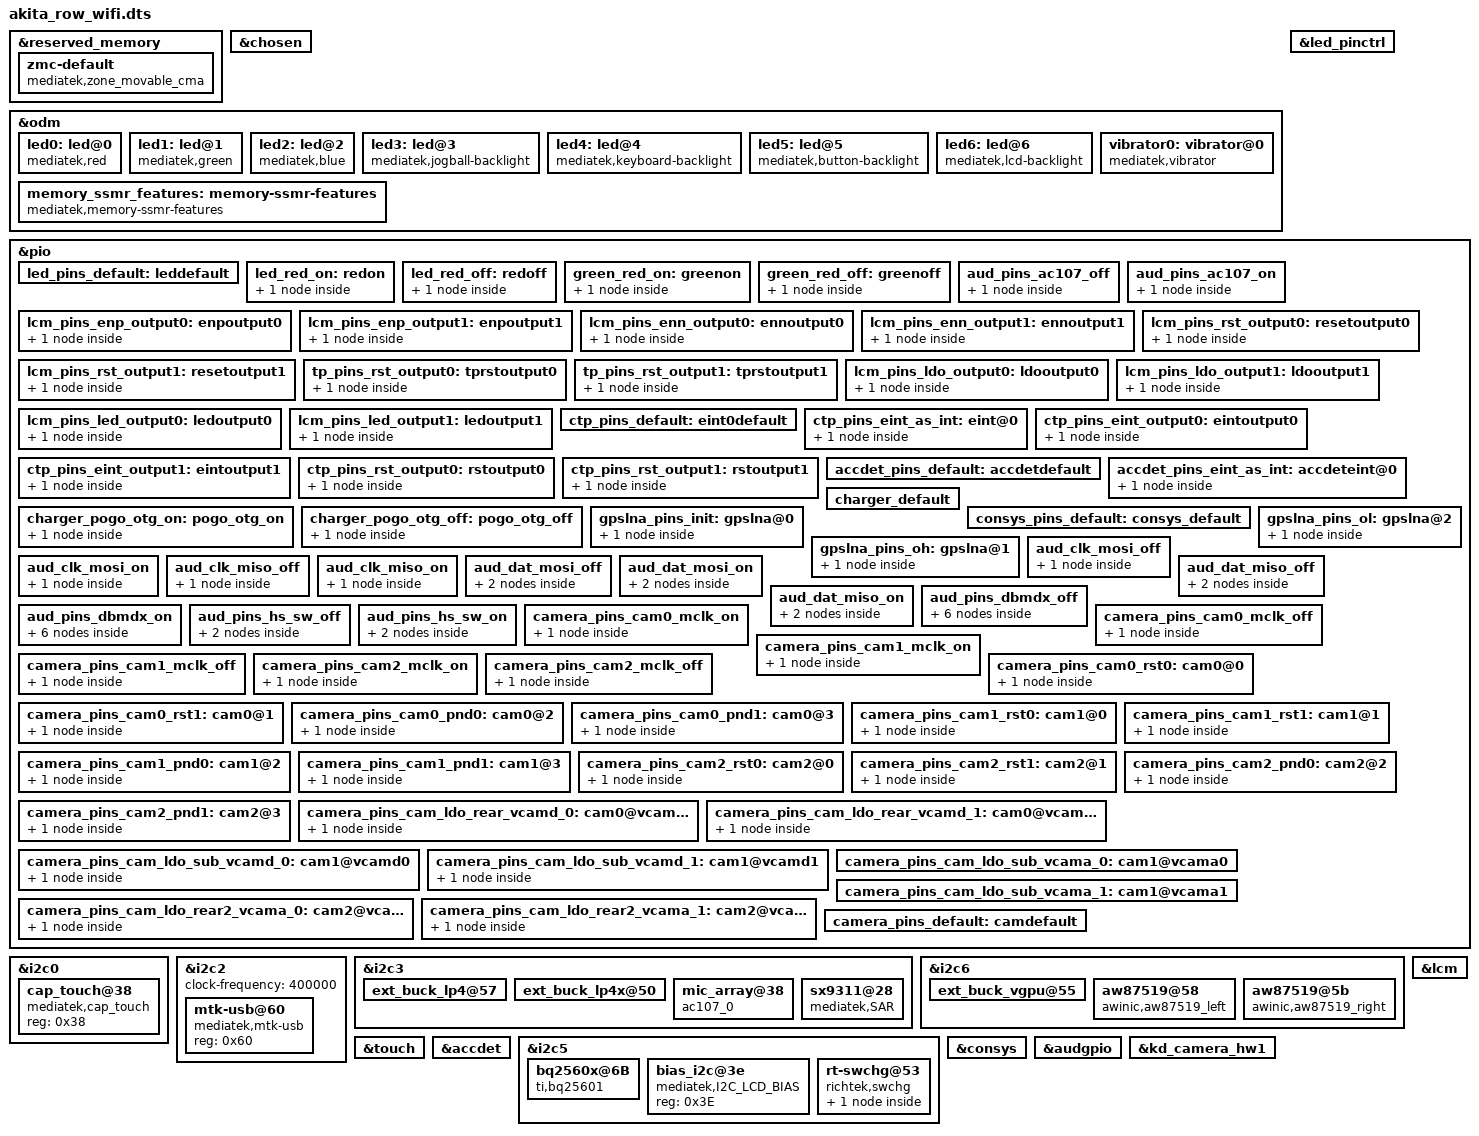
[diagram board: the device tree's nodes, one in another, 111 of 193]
#include <dt-bindings/interrupt-controller/arm-gic.h>
#include <dt-bindings/interrupt-controller/irq.h>
#include <dt-bindings/pinctrl/mt6761-pinfunc.h>
#include <dt-bindings/mmc/mt6761-msdc.h>
#include <dt-bindings/clock/mt6761-clk.h>

/dts-v1/;
/plugin/;

&reserved_memory {
	#address-cells = <2>;
	#size-cells = <2>;
	ranges;

	zmc-default {
		compatible = "mediatek,zone_movable_cma";
		size = <0 0xffc00000>;
		alignment = <0 0x10000000>;
		alloc-ranges = <0 0xc0000000 1 0x00000000>;
	};
};

/* chosen */
&chosen {

	/* fpga may has no lk, we need to specify display info here */
	/* fb buffer is reserved using this dts by memory node above */
	atag,videolfb-fb_base_h = <0x0>;
	atag,videolfb-fb_base_l = <0x5e605000>;
	atag,videolfb-islcmfound = <1>;
	/* because no lk, so lcm is not inited */
	atag,videolfb-islcm_inited = <0>;
	atag,videolfb-fps= <6000>;
	atag,videolfb-vramSize= <0x017bb000>;
	atag,videolfb-lcmname= "nt35521_hd_dsi_vdo_truly_rt5081_drv";
};

&odm {
	led0:led@0 {
		compatible = "mediatek,red";
		led_mode = <2>;
		data = <1>;
		pwm_config = <0 0 0 0 0>;
	};
	led1:led@1 {
		compatible = "mediatek,green";
		led_mode = <2>;
		data = <1>;
		pwm_config = <0 0 0 0 0>;
	};
	led2:led@2 {
		compatible = "mediatek,blue";
		led_mode = <3>;
		data = <2>;
		pwm_config = <0 0 0 0 0>;
	};
	led3:led@3 {
		compatible = "mediatek,jogball-backlight";
		led_mode = <0>;
		data = <1>;
		pwm_config = <0 0 0 0 0>;
	};
	led4:led@4 {
		compatible = "mediatek,keyboard-backlight";
		led_mode = <0>;
		data = <1>;
		pwm_config = <0 0 0 0 0>;
	};
	led5:led@5 {
		compatible = "mediatek,button-backlight";
		led_mode = <0>;
		data = <1>;
		pwm_config = <0 0 0 0 0>;
	};
	led6:led@6 {
		compatible = "mediatek,lcd-backlight";
		led_mode = <5>;
		data = <1>;
		pwm_config = <0 0 0 0 0>;
	};
	vibrator0:vibrator@0 {
		compatible = "mediatek,vibrator";
		vib_timer = <25>;
		vib_limit = <9>;
		vib_vol= <9>;
	};
	memory_ssmr_features: memory-ssmr-features {
		compatible = "mediatek,memory-ssmr-features";
		svp-size = <0 0>;
		iris-recognition-size = <0 0>;
		2d_fr-size = <0 0>;
		tui-size = <0 0>;
		wfd-size = <0 0>;
		prot-sharedmem-size = <0 0>;
	};
};

&led_pinctrl {
	pinctrl-names = "default", "red_on", "red_off", "green_on", "green_off";
	pinctrl-0 = <&led_pins_default>;
	pinctrl-1 = <&led_red_on>;
	pinctrl-2 = <&led_red_off>;
	pinctrl-3 = <&green_red_on>;
	pinctrl-4 = <&green_red_off>;
	status = "okay";
};

&pio {
	led_pins_default: leddefault {
	};
	led_red_on: redon {
		pins_cmd_dat {
			pinmux = <PINMUX_GPIO4__FUNC_GPIO4>;
			slew-rate = <1>;
			output-high;
		};
	};
	led_red_off: redoff {
		pins_cmd_dat {
			pinmux = <PINMUX_GPIO4__FUNC_GPIO4>;
			slew-rate = <1>;
			output-low;
		};
	};
	green_red_on:greenon {
		pins_cmd_dat {
			pinmux = <PINMUX_GPIO0__FUNC_GPIO0>;
			slew-rate = <1>;
			output-high;
		};
	};
	green_red_off: greenoff {
		pins_cmd_dat {
			pinmux = <PINMUX_GPIO0__FUNC_GPIO0>;
			slew-rate = <1>;
			output-low;
		};
	};
};


&i2c0 {
    cap_touch@38 {
        compatible = "mediatek,cap_touch" ;
        reg = < 0x38 > ;
        status = "okay" ;
    };
};

&i2c2 {
	#address-cells = <1>;
	#size-cells = <0>;
	clock-frequency = <400000>;

	mtk-usb@60 {
		compatible = "mediatek,mtk-usb";
		reg = <0x60>;
		status = "okay";
	};
};

&i2c3 {
	ext_buck_lp4@57 {
		regulator-name ="ext_buck_vdd2";
		regulator-min-microvolt = <300000>;
		regulator-max-microvolt = <1300000>;
		vsel_pin = <0>;
	};

	ext_buck_lp4x@50 {
		regulator-name ="ext_buck_vddq";
		regulator-min-microvolt = <300000>;
		regulator-max-microvolt = <1300000>;
		vsel_pin = <1>;
	};

	mic_array@38{
		compatible = "ac107_0";
		reg = <0x38>;
		pinctrl-names = "state_power_off","state_power_on";
		pinctrl-0 = <&aud_pins_ac107_off>;
		pinctrl-1 = <&aud_pins_ac107_on>;
	};

    sx9311@28 {
        compatible = "mediatek,SAR";
        reg = <0x28>;
	    interrupt-parent = <&pio>;
	    interrupts = <11 IRQ_TYPE_EDGE_FALLING 11 0>;
     	int-gpio = <&pio 11 0>;
        polling_mode			= <0>;
	    power_id   				= <0xffff>;
	    Semtech,reg-init        = < 0x03 0x70
		    						0x04 0x00
                                    0x10 0x27
		    						0x11 0x00
		    						0x12 0x0b
		    						0x13 0x0A
		    						0x14 0x25
			    					0x15 0xC3
			    					0x16 0x20 
			    					0x17 0x4C
			    					0x18 0x28 
			    					0x19 0x38
			    					0x1A 0x10
			    					0x1B 0x00
			    					0x1C 0x00
			    					0x1D 0x00
			    					0x1E 0x00
			    					0x1F 0x00
			    					0x20 0x00
			    					0x21 0x18
			    					0x22 0x25
			    					0x23 0x00
			    					0x2A 0x01>;
        status = "okay";
    };
};

&pio {
	aud_pins_ac107_off: aud_pins_ac107_off {
		pins_cmd_dat {
			pinmux = <PINMUX_GPIO87__FUNC_GPIO87>;
			slew-rate = <1>;
			output-low;
		};
	};
	aud_pins_ac107_on: aud_pins_ac107_on{
		pins_cmd_dat {
			pinmux = <PINMUX_GPIO87__FUNC_GPIO87>;
			slew-rate = <1>;
			output-high;
		};
	};
};

&i2c6 {
	ext_buck_vgpu@55 {
		regulator-name ="ext_buck_vgpu";
		regulator-min-microvolt = <300000>;
		regulator-max-microvolt = <1300000>;
		vsel_pin = <2>;
	};

	aw87519@58 {
		compatible = "awinic,aw87519_left";
		reg = <0x58>;
		reset-gpio = <&pio 174 0>;
		status = "okay";
	};

	aw87519@5b {
		compatible = "awinic,aw87519_right";
		reg = <0x5b>;
		reset-gpio = <&pio 153 0>;
		status = "okay";
	};
};

/*LCM start*/
&lcm {
	pinctrl-names = "state_enp_output0", "state_enp_output1",
			"state_enn_output0", "state_enn_output1",
			"state_reset_output0", "state_reset_output1",
			"state_tp_reset_output0", "state_tp_reset_output1",
			"state_ldo_output0", "state_ldo_output1",
			"state_led_output0", "state_led_output1";
	pinctrl-0 = <&lcm_pins_enp_output0>;
	pinctrl-1 = <&lcm_pins_enp_output1>;
	pinctrl-2 = <&lcm_pins_enn_output0>;
	pinctrl-3 = <&lcm_pins_enn_output1>;
	pinctrl-4 = <&lcm_pins_rst_output0>;
	pinctrl-5 = <&lcm_pins_rst_output1>;
	pinctrl-6 = <&tp_pins_rst_output0>;
	pinctrl-7 = <&tp_pins_rst_output1>;
	pinctrl-8 = <&lcm_pins_ldo_output0>;
	pinctrl-9 = <&lcm_pins_ldo_output1>;
	pinctrl-10 = <&lcm_pins_led_output0>;
	pinctrl-11 = <&lcm_pins_led_output1>;
	status = "okay";
};
&pio {
	lcm_pins_enp_output0: enpoutput0 {
		pins_cmd_dat {
			pinmux = <PINMUX_GPIO167__FUNC_GPIO167>;
			slew-rate = <1>;
			output-low;
		};
	};
	lcm_pins_enp_output1: enpoutput1 {
		pins_cmd_dat {
			pinmux = <PINMUX_GPIO167__FUNC_GPIO167>;
			slew-rate = <1>;
			output-high;
		};
	};
	lcm_pins_enn_output0: ennoutput0 {
		pins_cmd_dat {
			pinmux = <PINMUX_GPIO168__FUNC_GPIO168>;
			slew-rate = <1>;
			output-low;
		};
	};
	lcm_pins_enn_output1: ennoutput1 {
		pins_cmd_dat {
			pinmux = <PINMUX_GPIO168__FUNC_GPIO168>;
			slew-rate = <1>;
			output-high;
		};
	};
	lcm_pins_rst_output0: resetoutput0 {
		pins_cmd_dat {
			pinmux = <PINMUX_GPIO45__FUNC_GPIO45>;
			slew-rate = <1>;
			output-low;
		};
	};
	lcm_pins_rst_output1: resetoutput1 {
		pins_cmd_dat {
			pinmux = <PINMUX_GPIO45__FUNC_GPIO45>;
			slew-rate = <1>;
			output-high;
		};
	};
	tp_pins_rst_output0: tprstoutput0 {
		pins_cmd_dat {
			pinmux = <PINMUX_GPIO172__FUNC_GPIO172>;
			slew-rate = <1>;
			output-low;
		};
	};
	tp_pins_rst_output1: tprstoutput1 {
		pins_cmd_dat {
			pinmux = <PINMUX_GPIO172__FUNC_GPIO172>;
			slew-rate = <1>;
			output-high;
		};
	};
	lcm_pins_ldo_output0: ldooutput0 {
		pins_cmd_dat {
			pinmux = <PINMUX_GPIO152__FUNC_GPIO152>;
			slew-rate = <1>;
			output-low;
		};
	};
	lcm_pins_ldo_output1: ldooutput1 {
		pins_cmd_dat {
			pinmux = <PINMUX_GPIO152__FUNC_GPIO152>;
			slew-rate = <1>;
			output-high;
		};
	};
	lcm_pins_led_output0: ledoutput0 {
		pins_cmd_dat {
			pinmux = <PINMUX_GPIO154__FUNC_GPIO154>;
			slew-rate = <1>;
			output-low;
		};
	};
	lcm_pins_led_output1: ledoutput1 {
		pins_cmd_dat {
			pinmux = <PINMUX_GPIO154__FUNC_GPIO154>;
			slew-rate = <1>;
			output-high;
		};
	};
};
/*LCM end*/

#include "d8-spi-melon.dtsi"

/* TOUCH start */
&touch {
	tpd-resolution = <800 1280>;
	use-tpd-button = <0>;
	tpd-key-num = <3>;
	tpd-key-local= <139 172 158 0>;
	tpd-key-dim-local = <90 883 100 40 230
				 883 100 40 370 883 100 40 0 0 0 0>;
	tpd-max-touch-num = <10>;
	tpd-filter-enable = <0>;
	tpd-filter-pixel-density = <106>;
	tpd-filter-custom-prameters = <0 0 0 0 0 0 0 0 0 0 0 0>;
	tpd-filter-custom-speed = <0 0 0>;
	pinctrl-names = "default", "state_eint_as_int", "state_eint_output0",
		"state_eint_output1", "state_rst_output0", "state_rst_output1";
	pinctrl-0 = <&ctp_pins_default>;
	pinctrl-1 = <&ctp_pins_eint_as_int>;
	pinctrl-2 = <&ctp_pins_eint_output0>;
	pinctrl-3 = <&ctp_pins_eint_output1>;
	pinctrl-4 = <&ctp_pins_rst_output0>;
	pinctrl-5 = <&ctp_pins_rst_output1>;
	status = "okay";
};
&pio {
	ctp_pins_default: eint0default {
	};
	ctp_pins_eint_as_int: eint@0 {
		pins_cmd_dat {
			pinmux = <PINMUX_GPIO10__FUNC_GPIO10>;
			slew-rate = <0>;
			bias-disable;
		};
	};
	ctp_pins_eint_output0: eintoutput0 {
		pins_cmd_dat {
			pinmux = <PINMUX_GPIO10__FUNC_GPIO10>;
			slew-rate = <1>;
			output-low;
		};
	};
	ctp_pins_eint_output1: eintoutput1 {
		pins_cmd_dat {
			pinmux = <PINMUX_GPIO10__FUNC_GPIO10>;
			slew-rate = <1>;
			output-high;
		};
	};
	ctp_pins_rst_output0: rstoutput0 {
		pins_cmd_dat {
			pinmux = <PINMUX_GPIO172__FUNC_GPIO172>;
			slew-rate = <1>;
			output-low;
		};
	};
	ctp_pins_rst_output1: rstoutput1 {
		pins_cmd_dat {
			pinmux = <PINMUX_GPIO172__FUNC_GPIO172>;
			slew-rate = <1>;
			output-high;
		};
	};
};
/* TOUCH end */
&accdet {
	accdet-mic-vol = <6>;
	headset-mode-setting = <0x500 0x500 1 0x1f0 0x800 0x800 0x20 0x44>;
	accdet-plugout-debounce = <1>;
	accdet-mic-mode = <1>;
	headset-eint-level-pol = <8>;
	headset-three-key-threshold = <0 80 220 400>;
	headset-three-key-threshold-CDD = <0 121 192 600>;
	headset-four-key-threshold = <0 58 121 192 400>;
	pinctrl-names = "default", "state_eint_as_int";
	pinctrl-0 = <&accdet_pins_default>;
	pinctrl-1 = <&accdet_pins_eint_as_int>;
	status = "okay";
};
&pio {
	accdet_pins_default: accdetdefault {
	};
	accdet_pins_eint_as_int: accdeteint@0 {
		pins_cmd_dat {
			pinmux = <PINMUX_GPIO9__FUNC_GPIO9>;
			slew-rate = <0>;
			bias-disable;
		};
	};
};

&i2c5 {
	bq2560x@6B {
		compatible = "ti,bq25601";
		reg = <0x6B>;
	
		ti,bq2560x,usb-vlim = <4600>;
		ti,bq2560x,usb-ilim = <500>;
		ti,bq2560x,usb-vreg = <4400>;
		ti,bq2560x,usb-ichg = <500>;

		ti,bq2560x,precharge-current = <256>;
		ti,bq2560x,termination-current = <180>;
		ti,bq2560x,boost-voltage = <5150>;
		ti,bq2560x,boost-current = <1200>;
		ti,bq2560x,enable_term;
		ti,bq2560x,stat-pin-ctrl = <3>;
		ti,bq2560x,vac-ovp-threshold = <6500>;
		pinctrl-names = "default", "pogo_otg_on","pogo_otg_off";
		pinctrl-0 = <&charger_default>;
		pinctrl-1 = <&charger_pogo_otg_on>;
		pinctrl-2 = <&charger_pogo_otg_off>;

	};
	bias_i2c@3e {
		compatible = "mediatek,I2C_LCD_BIAS";
		reg = <0x3E>;
		status = "okay";
	};
	rt-swchg@53 {
                compatible = "richtek,swchg";
                reg = <0x53>;
                status = "okay";

                rt,intr_gpio_num = <2>; /* direct defined GPIO num */
                rt,intr_gpio = <&pio 2 0x0>; /* GPIO */
                rt9471 {
                        /*
                         * Charger name
                         * Main charger: primary_chg
                         * Slave charger: secondary_chg
                         */
                        charger_name = "primary_chg";
                        chg_alias_name = "rt9471_chg";
                        rm-slave-addr = /bits/ 8 <0x53>;
                        rm-name = "rt9471";
                        interrupt-names = "wdt", "chg_mivr", "vbus_gd",
                                          "bc12_done", "detach", "vac_ov",
                                          "otg_fault";
                        ichg = <1000000>;               /* uA */
                        aicr = <500000>;                /* uA */
                        mivr = <4400000>;               /* uV */
                        cv = <4350000>;                 /* uV */
                        ieoc = <200000>;                /* uA */
                        safe-tmr = <10>;                /* hour */
                        wdt = <40>;                     /* sec */
                        /*
                         * 0: MIVR register
                         * 1: MIVR = VBAT + 200mV
                         * 2: MIVR = VBAT + 250mV
                         * >= 3: MIVR = VBAT + 300mV
                         */
                        mivr-track = <0>;
                        en-te;
                        /* en-jeita; */
                        /* ceb-invert; */
                        /* dis-i2c-tout; */
                        en-qon-rst;
                        /* auto-aicr; */
                };
        };
};

&pio {
	charger_default: charger_default {
	};
	charger_pogo_otg_on: pogo_otg_on {
		pins_cmd_dat {
			pinmux = <PINMUX_GPIO169__FUNC_GPIO169>;
			slew-rate = <1>;
			output-high;
		};
	};
	charger_pogo_otg_off: pogo_otg_off {
		pins_cmd_dat {
			pinmux = <PINMUX_GPIO169__FUNC_GPIO169>;
			slew-rate = <1>;
			output-low;
		};
	};
};

/* CONSYS GPIO standardization */
&pio {
	consys_pins_default: consys_default {
	};
	gpslna_pins_init: gpslna@0 {
		pins_cmd_dat {
			pinmux = <PINMUX_GPIO91__FUNC_GPIO91>;
			slew-rate = <0>;
			bias-disable;
			output-low;
		};
	};
	gpslna_pins_oh: gpslna@1 {
		pins_cmd_dat {
			pinmux = <PINMUX_GPIO91__FUNC_GPIO91>;
			slew-rate = <1>;
			output-high;
		};
	};
	gpslna_pins_ol: gpslna@2 {
		pins_cmd_dat {
			pinmux = <PINMUX_GPIO91__FUNC_GPIO91>;
			slew-rate = <1>;
			output-low;
		};
	};
};
&consys {
	pinctrl-names = "default", "gps_lna_state_init",
		"gps_lna_state_oh", "gps_lna_state_ol";
	pinctrl-0 = <&consys_pins_default>;
	pinctrl-1 = <&gpslna_pins_init>;
	pinctrl-2 = <&gpslna_pins_oh>;
	pinctrl-3 = <&gpslna_pins_ol>;
	status = "okay";
};
/* CONSYS end */

/* AUDIO GPIO standardization */
&audgpio {
	pinctrl-names = "aud_clk_mosi_off",
			"aud_clk_mosi_on",
			"aud_clk_miso_off",
			"aud_clk_miso_on",
			"aud_dat_mosi_off",
			"aud_dat_mosi_on",
			"aud_dat_miso_off",
			"aud_dat_miso_on",
			"aud_dbmdx_off",
			"aud_dbmdx_on",
			"aud_hs_sw_off",
			"aud_hs_sw_on";
	pinctrl-0 = <&aud_clk_mosi_off>;
	pinctrl-1 = <&aud_clk_mosi_on>;
	pinctrl-2 = <&aud_clk_miso_off>;
	pinctrl-3 = <&aud_clk_miso_on>;
	pinctrl-4 = <&aud_dat_mosi_off>;
	pinctrl-5 = <&aud_dat_mosi_on>;
	pinctrl-6 = <&aud_dat_miso_off>;
	pinctrl-7 = <&aud_dat_miso_on>;
	pinctrl-8 = <&aud_pins_dbmdx_off>;
	pinctrl-9 = <&aud_pins_dbmdx_on>;
	pinctrl-10 = <&aud_pins_hs_sw_off>;
	pinctrl-11 = <&aud_pins_hs_sw_on>;
	status = "okay";
};

&pio {
	aud_clk_mosi_off: aud_clk_mosi_off {
		pins_cmd0_dat {
			pinmux = <PINMUX_GPIO136__FUNC_GPIO136>;
		};
	};

	aud_clk_mosi_on: aud_clk_mosi_on {
		pins_cmd0_dat {
			pinmux = <PINMUX_GPIO136__FUNC_AUD_CLK_MOSI>;
		};
	};

	aud_clk_miso_off: aud_clk_miso_off {
		pins_cmd0_dat {
			pinmux = <PINMUX_GPIO140__FUNC_GPIO140>;
		};
	};

	aud_clk_miso_on: aud_clk_miso_on {
		pins_cmd0_dat {
			pinmux = <PINMUX_GPIO140__FUNC_AUD_CLK_MISO>;
		};
	};

	aud_dat_mosi_off: aud_dat_mosi_off {
		pins_cmd1_dat {
			pinmux = <PINMUX_GPIO138__FUNC_GPIO138>;
			input-enable;
			slew-rate = <0>;
			bias-disable;
		};
		pins_cmd2_dat {
			pinmux = <PINMUX_GPIO139__FUNC_GPIO139>;
			input-enable;
			slew-rate = <0>;
			bias-disable;
		};
	};

	aud_dat_mosi_on: aud_dat_mosi_on {
		pins_cmd1_dat {
			pinmux = <PINMUX_GPIO138__FUNC_AUD_DAT_MOSI0>;
		};
		pins_cmd2_dat {
			pinmux = <PINMUX_GPIO139__FUNC_AUD_DAT_MOSI1>;
		};
	};

	aud_dat_miso_off: aud_dat_miso_off {
		pins_cmd1_dat {
			pinmux = <PINMUX_GPIO142__FUNC_GPIO142>;
			input-enable;
			slew-rate = <0>;
			bias-disable;
		};
		pins_cmd2_dat {
			pinmux = <PINMUX_GPIO143__FUNC_GPIO143>;
			input-enable;
			slew-rate = <0>;
			bias-disable;
		};
	};

	aud_dat_miso_on: aud_dat_miso_on {
		pins_cmd1_dat {
			pinmux = <PINMUX_GPIO142__FUNC_AUD_DAT_MISO0>;
		};
		pins_cmd2_dat {
			pinmux = <PINMUX_GPIO143__FUNC_AUD_DAT_MISO1>;
		};
	};

	aud_pins_dbmdx_off: aud_pins_dbmdx_off {
		pins_cmd0_dat {
			pinmux = <PINMUX_GPIO14__FUNC_GPIO14>;
		};
		pins_cmd1_dat {
			pinmux = <PINMUX_GPIO15__FUNC_GPIO15>;
		};
		pins_cmd2_dat {
			pinmux = <PINMUX_GPIO17__FUNC_GPIO17>;
		};
		pins_cmd3_dat {
			pinmux = <PINMUX_GPIO18__FUNC_GPIO18>;
		};
		pins_cmd4_dat {
			pinmux = <PINMUX_GPIO19__FUNC_GPIO19>;
		};
		pins_cmd5_dat {
			pinmux = <PINMUX_GPIO20__FUNC_GPIO20>;
		};
	};

	aud_pins_dbmdx_on: aud_pins_dbmdx_on {
		pins_cmd0_dat {
			pinmux = <PINMUX_GPIO14__FUNC_I2S0_BCK>;
		};
		pins_cmd1_dat {
			pinmux = <PINMUX_GPIO15__FUNC_I2S0_LRCK>;
		};
		pins_cmd2_dat {
			pinmux = <PINMUX_GPIO17__FUNC_I2S0_DI>;
		};
		pins_cmd3_dat {
			pinmux = <PINMUX_GPIO18__FUNC_I2S3_BCK>;
		};
		pins_cmd4_dat {
			pinmux = <PINMUX_GPIO19__FUNC_I2S3_LRCK>;
		};
		pins_cmd5_dat {
			pinmux = <PINMUX_GPIO20__FUNC_I2S3_DO>;
		};
	};
	aud_pins_hs_sw_off: aud_pins_hs_sw_off {
		pins_cmd0_dat {
			pinmux = <PINMUX_GPIO107__FUNC_GPIO107>;
			slew-rate = <1>;
			output-low;
		};
		pins_cmd1_dat {
			pinmux = <PINMUX_GPIO160__FUNC_GPIO160>;
			slew-rate = <1>;
			output-low;
		};
	};

	aud_pins_hs_sw_on: aud_pins_hs_sw_on {
		pins_cmd0_dat {
			pinmux = <PINMUX_GPIO107__FUNC_GPIO107>;
			slew-rate = <1>;
			output-high;
		};
		pins_cmd1_dat {
			pinmux = <PINMUX_GPIO160__FUNC_GPIO160>;
			slew-rate = <1>;
			output-high;
		};
	};
};
/* AUDIO end */

&pio {
	camera_pins_cam0_mclk_on: camera_pins_cam0_mclk_on {
		pins_cmd_dat {
			pinmux = <PINMUX_GPIO99__FUNC_CMMCLK0>;
		};
	};
	camera_pins_cam0_mclk_off: camera_pins_cam0_mclk_off {
		pins_cmd_dat {
			pinmux = <PINMUX_GPIO99__FUNC_GPIO99>;
		};
	};
	camera_pins_cam1_mclk_on: camera_pins_cam1_mclk_on {
		pins_cmd_dat {
			pinmux = <PINMUX_GPIO100__FUNC_CMMCLK1>;
		};
	};
	camera_pins_cam1_mclk_off: camera_pins_cam1_mclk_off {
		pins_cmd_dat {
			pinmux = <PINMUX_GPIO100__FUNC_GPIO100>;
		};
	};
	camera_pins_cam2_mclk_on: camera_pins_cam2_mclk_on {
		pins_cmd_dat {
			pinmux = <PINMUX_GPIO108__FUNC_CMMCLK2>;
		};
	};
	camera_pins_cam2_mclk_off: camera_pins_cam2_mclk_off {
		pins_cmd_dat {
			pinmux = <PINMUX_GPIO108__FUNC_GPIO108>;
		};
	};
	camera_pins_cam0_rst0: cam0@0 {
		pins_cmd_dat {
			pinmux = <PINMUX_GPIO101__FUNC_GPIO101>;
			slew-rate = <1>;
			output-low;
		};
	};
	camera_pins_cam0_rst1: cam0@1 {
		pins_cmd_dat {
			pinmux = <PINMUX_GPIO101__FUNC_GPIO101>;
			slew-rate = <1>;
			output-high;
		};
	};
	camera_pins_cam0_pnd0: cam0@2 {
		pins_cmd_dat {
			pinmux = <PINMUX_GPIO97__FUNC_GPIO97>;
			slew-rate = <1>;
			output-low;
		};
	};
	camera_pins_cam0_pnd1: cam0@3 {
		pins_cmd_dat {
			pinmux = <PINMUX_GPIO97__FUNC_GPIO97>;
			slew-rate = <1>;
			output-high;
		};
	};
	camera_pins_cam1_rst0: cam1@0 {
		pins_cmd_dat {
			pinmux = <PINMUX_GPIO102__FUNC_GPIO102>;
			slew-rate = <1>;
			output-low;
		};
	};
	camera_pins_cam1_rst1: cam1@1 {
		pins_cmd_dat {
			pinmux = <PINMUX_GPIO102__FUNC_GPIO102>;
			slew-rate = <1>;
			output-high;
		};
	};
	camera_pins_cam1_pnd0: cam1@2 {
		pins_cmd_dat {
			pinmux = <PINMUX_GPIO98__FUNC_GPIO98>;
			slew-rate = <1>;
			output-low;
		};
	};
	camera_pins_cam1_pnd1: cam1@3 {
		pins_cmd_dat {
			pinmux = <PINMUX_GPIO98__FUNC_GPIO98>;
			slew-rate = <1>;
			output-high;
		};
	};
	camera_pins_cam2_rst0: cam2@0 {
		pins_cmd_dat {
			pinmux = <PINMUX_GPIO87__FUNC_GPIO87>;
			slew-rate = <1>;
			output-low;
		};
	};
	camera_pins_cam2_rst1: cam2@1 {
		pins_cmd_dat {
			pinmux = <PINMUX_GPIO87__FUNC_GPIO87>;
			slew-rate = <1>;
			output-high;
		};
	};
	camera_pins_cam2_pnd0: cam2@2 {
		pins_cmd_dat {
			pinmux = <PINMUX_GPIO160__FUNC_GPIO160>;
			slew-rate = <1>;
			output-low;
		};
	};
	camera_pins_cam2_pnd1: cam2@3 {
		pins_cmd_dat {
			pinmux = <PINMUX_GPIO160__FUNC_GPIO160>;
			slew-rate = <1>;
			output-high;
		};
	};
	camera_pins_cam_ldo_rear_vcamd_0: cam0@vcamd0 {
		pins_cmd_dat {
			pinmux = <PINMUX_GPIO88__FUNC_GPIO88>;
			slew-rate = <1>;
			output-low;
		};
	};
	camera_pins_cam_ldo_rear_vcamd_1: cam0@vcamd1 {
		pins_cmd_dat {
			pinmux = <PINMUX_GPIO88__FUNC_GPIO88>;
			slew-rate = <1>;
			output-high;
		};
	};
	camera_pins_cam_ldo_sub_vcamd_0: cam1@vcamd0 {
		pins_cmd_dat {
			pinmux = <PINMUX_GPIO170__FUNC_GPIO170>;
			slew-rate = <1>;
			output-low;
		};
	};
	camera_pins_cam_ldo_sub_vcamd_1: cam1@vcamd1 {
		pins_cmd_dat {
			pinmux = <PINMUX_GPIO170__FUNC_GPIO170>;
			slew-rate = <1>;
			output-high;
		};
	};
	camera_pins_cam_ldo_sub_vcama_0: cam1@vcama0 {

	};
	camera_pins_cam_ldo_sub_vcama_1: cam1@vcama1 {

	};
	camera_pins_cam_ldo_rear2_vcama_0: cam2@vcama0 {
		pins_cmd_dat {
			pinmux = <PINMUX_GPIO159__FUNC_GPIO159>;
			slew-rate = <1>;
			output-low;
		};
	};
	camera_pins_cam_ldo_rear2_vcama_1: cam2@vcama1 {
		pins_cmd_dat {
			pinmux = <PINMUX_GPIO159__FUNC_GPIO159>;
			slew-rate = <1>;
			output-high;
		};
	};
	camera_pins_default: camdefault {
	};

};

&kd_camera_hw1 {
	pinctrl-names = "default",
			"cam0_rst0",
			"cam0_rst1",
			"cam0_pnd0",
			"cam0_pnd1",
			"cam1_rst0",
			"cam1_rst1",
			"cam1_pnd0",
			"cam1_pnd1",
			"cam2_rst0",
			"cam2_rst1",
			"cam2_pnd0",
			"cam2_pnd1",
			"cam0_vcamd_on",
			"cam0_vcamd_off",
			"cam1_vcamd_on",
			"cam1_vcamd_off",
			"cam1_vcama_on",
			"cam1_vcama_off",
			"cam2_vcama_on",
			"cam2_vcama_off",
			"cam0_mclk_on",
			"cam0_mclk_off",
			"cam1_mclk_on",
			"cam1_mclk_off",
			"cam2_mclk_on",
			"cam2_mclk_off";

	pinctrl-0 = <&camera_pins_default>;
	pinctrl-1 = <&camera_pins_cam0_rst0>;
	pinctrl-2 = <&camera_pins_cam0_rst1>;
	pinctrl-3 = <&camera_pins_cam0_pnd0>;
	pinctrl-4 = <&camera_pins_cam0_pnd1>;
	pinctrl-5 = <&camera_pins_cam1_rst0>;
	pinctrl-6 = <&camera_pins_cam1_rst1>;
	pinctrl-7 = <&camera_pins_cam1_pnd0>;
	pinctrl-8 = <&camera_pins_cam1_pnd1>;
	pinctrl-9 = <&camera_pins_cam2_rst0>;
	pinctrl-10 = <&camera_pins_cam2_rst1>;
	pinctrl-11 = <&camera_pins_cam2_pnd0>;
	pinctrl-12 = <&camera_pins_cam2_pnd1>;
	pinctrl-13 = <&camera_pins_cam_ldo_rear_vcamd_1>;
	pinctrl-14 = <&camera_pins_cam_ldo_rear_vcamd_0>;
	pinctrl-15 = <&camera_pins_cam_ldo_sub_vcamd_1>;
	pinctrl-16 = <&camera_pins_cam_ldo_sub_vcamd_0>;
	pinctrl-17 = <&camera_pins_cam_ldo_sub_vcama_1>;
	pinctrl-18 = <&camera_pins_cam_ldo_sub_vcama_0>;
	pinctrl-19 = <&camera_pins_cam_ldo_rear2_vcama_1>;
	pinctrl-20 = <&camera_pins_cam_ldo_rear2_vcama_0>;
	pinctrl-21 = <&camera_pins_cam0_mclk_on>;
	pinctrl-22 = <&camera_pins_cam0_mclk_off>;
	pinctrl-23 = <&camera_pins_cam1_mclk_on>;
	pinctrl-24 = <&camera_pins_cam1_mclk_off>;
	pinctrl-25 = <&camera_pins_cam2_mclk_on>;
	pinctrl-26 = <&camera_pins_cam2_mclk_off>;
	status = "okay";

};

#include <akita_row_wifi/cust.dtsi>
/*End of this file, DO NOT ADD ANYTHING HERE*/
